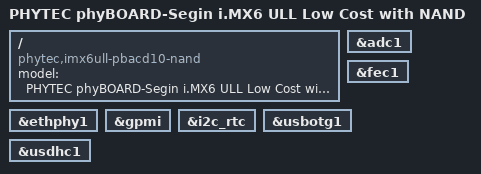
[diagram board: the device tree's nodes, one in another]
// SPDX-License-Identifier: (GPL-2.0+ OR MIT)
/*
 * Copyright (C) 2019 PHYTEC Messtechnik GmbH
 * Author: Stefan Riedmueller <s.riedmueller@phytec.de>
 */

/dts-v1/;
#include "imx6ull.dtsi"
#include "imx6ull-phytec-phycore-som.dtsi"
#include "imx6ull-phytec-segin.dtsi"
#include "imx6ull-phytec-segin-peb-eval-01.dtsi"
#include "imx6ull-phytec-segin-peb-wlbt-05.dtsi"

/ {
	model = "PHYTEC phyBOARD-Segin i.MX6 ULL Low Cost with NAND";
	compatible = "phytec,imx6ull-pbacd10-nand", "phytec,imx6ull-pbacd10",
		     "phytec,imx6ull-pcl063", "fsl,imx6ull";
};

&adc1 {
	status = "okay";
};

&ethphy1 {
	status = "okay";
};

&fec1 {
	status = "okay";
};

&gpmi {
	status = "okay";
};

&i2c_rtc {
	status = "okay";
};

&usbotg1 {
	status = "okay";
};

&usdhc1 {
	status = "okay";
};
